# ISD9100_v3 register map
File version: 1.0
Registers are 32-bit, read-write, reset 0x0 unless marked. A register's access mark holds for its fields unless they carry their own. Offsets are from the block's base; [hi:lo] are bit positions; {n}, {i} and the like mark numbered series.

## PDMA — PDMA Register Map
Base 0x50008000
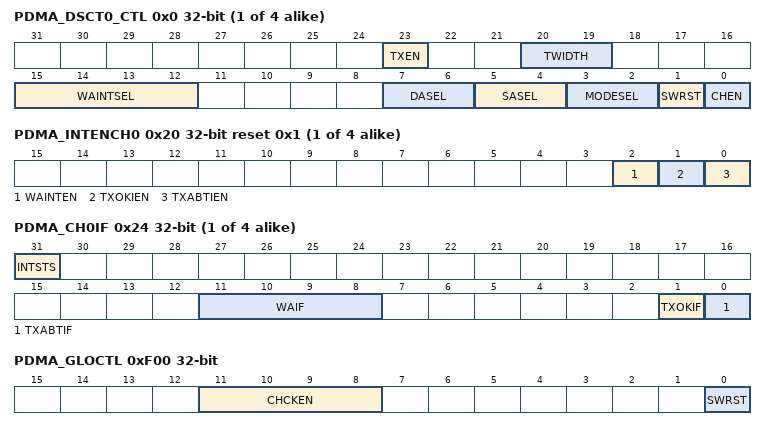
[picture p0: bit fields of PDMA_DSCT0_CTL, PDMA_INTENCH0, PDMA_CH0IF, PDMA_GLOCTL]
{0x0+0x100*i} PDMA_DSCT{i}_CTL (i=0..3) — PDMA Control Register of Channel 0
  [23] TXEN — Trigger Enable - Start a PDMA operation. Note: When PDMA transfer completed, this bit will be cleared automatically. If a bus error occurs, all PDMA transfer will be stopped. Software must reset PDMA channel, and then trigger again.
    0=Write: no effect. Read: Idle/Finished; 1=Enable PDMA data read or write transfer
  [20:19] TWIDTH — Peripheral Transfer Width Select. This parameter determines the data width to be transferred each PDMA transfer operation. Note: This field is meaningful only when MODESEL is IP to Memory mode (APB-to-Memory) or Memory to IP mode (Memory-to-APB).
    0=One word (32 bits) is transferred for every PDMA operation; 1=One byte (8 bits) is transferred for every PDMA operation; 2=One half-word (16 bits) is transferred for every PDMA operation
  [15:12] WAINTSEL — Wrap Interrupt Select x1xx: If this bit is set, and wraparound mode is in operation a Wrap Interrupt can be generated when half each PDMA transfer is complete. For example if BYTECNT aaa 32 then an interrupt could be generated when 16 bytes were sent. xxx1: If this bit is set, and wraparound mode is in operation a Wrap Interrupt can be generated when each PDMA transfer is wrapped. For example if BYTECNT aaa 32 then an interrupt could be generated when 32 bytes were sent and PDMA wraps around. x1x1: Both half and w interrupts generated.
  [7:6] DASEL — Destination Address Select. This parameter determines the behavior of the current destination address register with each PDMA transfer. It can either be fixed, incremented or wrapped.
    0=Transfer Destination Address is incremented; 2=Transfer Destination Address is fixed (Used when data transferred from multiple addresses to a single destination such as peripheral FIFO input); 3=Transfer Destination Address is wrapped. When PDMA_CURBCCHn (Current Byte Count) equals zero, the PDMA_CURDACHn (Current Destination Address) and PDMA_CURBCCHn registers will be reloaded from the PDMA_DSCTn_ENDDA (Destination Address) and PDMA_TXBCCHn (Byte Count) registers automatically and PDMA will start another transfer. Cycle continues until software sets PDMACKEN=0. When PDMACKEN is disabled, the PDMA will complete the active transfer but the remaining data in the SBUF will not be transferred to the destination address
  [5:4] SASEL — Source Address Select. This parameter determines the behavior of the current source address register with each PDMA transfer. It can either be fixed, incremented or wrapped.
    0=Transfer Source address is incremented; 2=Transfer Source address is fixed; 3=Transfer Source address is wrapped. When PDMA_CURBCCHn (Current Byte Count) equals zero, the PDMA_CURSACHn (Current Source Address) and PDMA_CURBCCHn registers will be reloaded from the PDMA_DSCTn_ENDSA (Source Address) and PDMA_TXBCCHn (Byte Count) registers automatically and PDMA will start another transfer. Cycle continues until software sets PDMACKEN aaa 0. When PDMACKEN is disabled, the PDMA will complete the active transfer but the remaining data in the SBUF will not be transferred to the destination address
  [3:2] MODESEL — PDMA Mode Select. This parameter selects to transfer direction of the PDMA channel. Possible values are:
    0=Memory to Memory mode (SRAM-to-SRAM); 1=IP to Memory mode (APB-to-SRAM); 2=Memory to IP mode (SRAM-to-APB)
  [1] SWRST — Software Engine Reset
    0=Writing 0 to this bit has no effect; 1=Writing 1 to this bit will reset the internal state machine and pointers. The contents of the control register will not be cleared. This bit will auto clear after a few clock cycles
  [0] CHEN — PDMA Channel Enable. Setting this bit to 1 enables PDMA's operation. If this bit is cleared, PDMA will ignore all PDMA request and force Bus Master into IDLE state. Note: SWRST will clear this bit.
{0x4+0x100*i} PDMA_DSCT{i}_ENDSA (i=0..3) — PDMA Transfer Source Address Register of Channel 0
  [31:0] ENDSA — PDMA Transfer Source Address Register. This register holds the initial Source Address of PDMA transfer. Note: The source address must be word aligned.
{0x8+0x100*i} PDMA_DSCT{i}_ENDDA (i=0..3) — PDMA Transfer Destination Address Register of Channel 0
  [31:0] ENDDA — PDMA Transfer Destination Address Register. This register holds the initial Destination Address of PDMA transfer. Note: The destination address must be word aligned.
{0xC+0x100*i} PDMA_TXBCCH{i} (i=0..3) — PDMA Transfer Byte Count Register of Channel 0
  [15:0] BYTECNT — PDMA Transfer Byte Count Register. This register controls the transfer byte count of PDMA. Maximum value is 0xFFFF. Note: When in memory-to-memory (PDMA_DSCTn_CTL.MODESEL aaa 00b) mode, the transfer byte count must be word aligned, that is multiples of 4bytes.
{0x10+0x100*i} PDMA_INLBPCH{i} ro (i=0..3) — PDMA Internal Buffer Pointer Register of Channel 0
  [3:0] BUFPTR — PDMA Internal Buffer Pointer Register (Read Only). A PDMA transaction consists of two stages, a read from the source address and a write to the destination address. Internally this data is buffered in a 32bit register. If transaction width between the read and write transactions are different, this register tracks which byte/half-word of the internal buffer is being processed by the current transaction.
{0x14+0x100*i} PDMA_CURSACH{i} ro (i=0..3) — PDMA Current Source Address Register of Channel 0
  [31:0] CURSA — PDMA Current Source Address Register (Read Only). This register returns the source address from which the PDMA transfer is occurring. This register is loaded from PDMA_DSCTn_ENDSA when PDMA is triggered or when a wraparound occurs.
{0x18+0x100*i} PDMA_CURDACH{i} ro (i=0..3) — PDMA Current Destination Address Register of Channel 0
  [31:0] CURDA — PDMA Current Destination Address Register (Read Only). This register returns the destination address to which the PDMA transfer is occurring. This register is loaded from PDMA_DSCTn_ENDDA when PDMA is triggered or when a wraparound occurs.
{0x1C+0x100*i} PDMA_CURBCCH{i} ro (i=0..3) — PDMA Current Byte Count Register of Channel 0
  [15:0] CURBC — PDMA Current Byte Count Register (Read Only). This field indicates the current remaining byte count of PDMA transfer. This register is initialized with PDMA_TXBCCHn register when PDMA is triggered or when a wraparound occurs
{0x20+0x100*i} PDMA_INTENCH{i} reset 0x1 (i=0..3) — PDMA Interrupt Enable Control Register of Channel 0
  [2] WAINTEN — Wraparound Interrupt Enable. If enabled, and channel source or destination address is in wraparound mode, the PDMA controller will generate a WRAP interrupt to the CPU according to the setting of PDMA_DSCTn_CTL.WAINTSEL. This can be interrupts when the transaction has finished and has wrapped around and/or when the transaction is half way in progress. This allows the efficient implementation of circular buffers for DMA.
    0=Disable Wraparound PDMA interrupt generation; 1=Enable Wraparound interrupt generation
  [1] TXOKIEN — PDMA Transfer Done Interrupt Enable. If enabled, the PDMA controller will generate and interrupt to the CPU when the requested PDMA transfer is complete.
    0=Disable PDMA transfer done interrupt generation; 1=Enable PDMA transfer done interrupt generation
  [0] TXABTIEN — PDMA Read/Write Target Abort Interrupt Enable. If enabled, the PDMA controller will generate and interrupt to the CPU whenever a PDMA transaction is aborted due to an error. If a transfer is aborted, PDMA channel must be reset to resume DMA operation.
    0=Disable PDMA transfer target abort interrupt generation; 1=Enable PDMA transfer target abort interrupt generation
{0x24+0x100*i} PDMA_CH{i}IF (i=0..3) — PDMA Interrupt Status Register of Channel 0
  [31] INTSTS ro — Interrupt Pin Status (Read Only). This bit is the Interrupt pin status of PDMA channel.
  [11:8] WAIF — Wrap Around Transfer Byte Count Interrupt Flag. These flags are set whenever the conditions for a wraparound interrupt (complete or half complete) are met. They are cleared by writing one to the bits. 0001 aaa Current transfer finished flag (CURBC aaaaaa 0). 0100 aaa Current transfer half complete flag (CURBC aaaaaa BYTECNT/2).
  [1] TXOKIF — Block Transfer Done Interrupt Flag. This bit indicates that PDMA block transfer complete interrupt has been generated. It is cleared by writing 1 to the bit.
    0=Transfer ongoing or Idle; 1=Transfer Complete
  [0] TXABTIF — PDMA Read/Write Target Abort Interrupt Flag. This flag indicates a Target Abort interrupt condition has occurred. This condition can happen if attempt is made to read/write from invalid or non-existent memory space. It occurs when PDMA controller receives a bus error from AHB master. Upon occurrence PDMA will stop transfer and go to idle state. To resume, software must reset PDMA channel and initiate transfer again. NOTE: This bit is cleared by writing 1 to itself.
    0=No bus ERROR response received; 1=Bus ERROR response received
0xF00 PDMA_GLOCTL — PDMA Global Control Register
  [11:8] CHCKEN — PDMA Controller Channel Clock Enable Control. To enable clock for channel n CHCKEN[n] must be set. CHCKEN[n] aaa 1: Enable Channel n clock. CHCKEN[n] aaa 0: Disable Channel n clock
  [0] SWRST — PDMA Software Reset. Note: This bit can reset all channels (global reset).
    0=Writing 0 to this bit has no effect; 1=Writing 1 to this bit will reset the internal state machine and pointers. The contents of control register will not be cleared. This bit will auto clear after several clock cycles
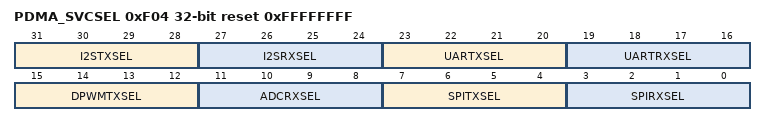
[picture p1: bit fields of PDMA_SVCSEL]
0xF04 PDMA_SVCSEL reset 0xFFFFFFFF — PDMA Service Selection Control Register
  [31:28] I2STXSEL — PDMA I2S Transmit Selection. This field defines which PDMA channel is connected to I2S peripheral transmit (PDMA destination) request.
  [27:24] I2SRXSEL — PDMA I2S Receive Selection. This field defines which PDMA channel is connected to I2S peripheral receive (PDMA source) request.
  [23:20] UARTXSEL — PDMA UART0 Transmit Selection. This field defines which PDMA channel is connected to UART0 peripheral transmit (PDMA destination) request.
  [19:16] UARTRXSEL — PDMA UART0 Receive Selection. This field defines which PDMA channel is connected to UART0 peripheral receive (PDMA source) request.
  [15:12] DPWMTXSEL — PDMA DPWM Transmit Selection. This field defines which PDMA channel is connected to DPWM peripheral transmit (PDMA destination) request.
  [11:8] ADCRXSEL — PDMA ADC Receive Selection. This field defines which PDMA channel is connected to ADC peripheral receive (PDMA source) request.
  [7:4] SPITXSEL — PDMA SPI0 Transmit Selection. This field defines which PDMA channel is connected to SPI0 peripheral transmit (PDMA destination) request.
  [3:0] SPIRXSEL — PDMA SPI0 Receive Selection. This field defines which PDMA channel is connected to SPI0 peripheral receive (PDMA source) request.
0xF0C PDMA_GLOBALIF ro — PDMA Global Interrupt Status Register
  [3:0] GLOBALIF — Interrupt Pin Status (Read Only). GLOBALIF[n] is the interrupt status of PDMA channel n.
